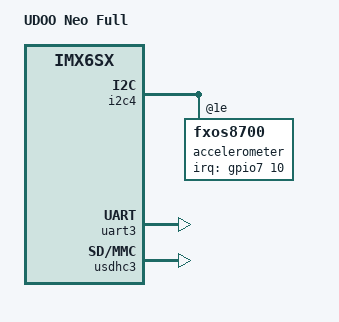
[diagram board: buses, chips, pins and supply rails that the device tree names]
/*
 * Copyright (C) 2015 Jasbir Matharu
 * Author: Ettore Chimenti <ek5.chimenti@gmail.com>
 *
 * This program is free software; you can redistribute it and/or modify
 * it under the terms of the GNU General Public License version 2 as
 * published by the Free Software Foundation.
 */

#include <dt-bindings/gpio/gpio.h>
#include <dt-bindings/interrupt-controller/irq.h>

/ {
	model = "UDOO Neo Full";
	compatible = "fsl,imx6sx-sdb", "fsl,imx6sx";

	/*aliases {
		fxos8700 = &accelerometer;
	};*/
  
};


&i2c4 { /* Onboard Motion sensors */
	  #address-cells = <1>;
    #size-cells = <0>;
    #interrupt-cell = <2>;
    status = "okay";

    accelerometer: fxos8700@1e {
      interrupt-parent = <&gpio7>;
      interrupts = <10 IRQ_TYPE_EDGE_BOTH>;
    };

   /* gyroscope: fxas2100x@20 {
    status = "okay";
  };*/
};

&uart3 { /* Bluetooth */
	status = "okay";
};

&usdhc3 { /* WiFi */
	status = "okay";
};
